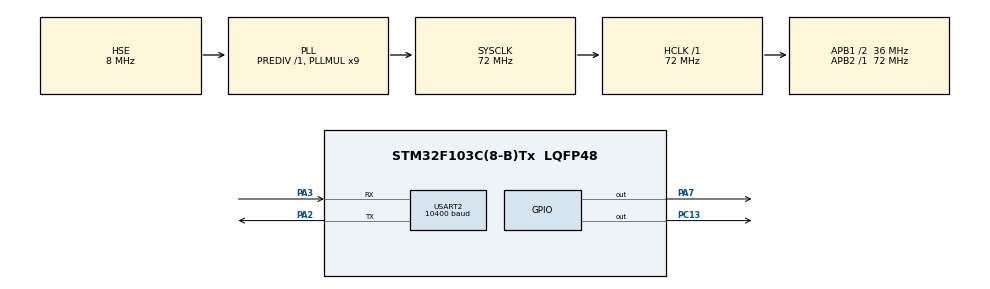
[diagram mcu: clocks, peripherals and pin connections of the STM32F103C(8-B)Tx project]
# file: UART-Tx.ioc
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Mcu.Family=STM32F1
Mcu.Name=STM32F103C(8-B)Tx
Mcu.Package=LQFP48
NVIC.PriorityGroup=NVIC_PRIORITYGROUP_4
NVIC.USART2_IRQn=true\:0\:0\:false\:false\:true\:true\:true\:true
PA13.Mode=Serial_Wire
PA13.Signal=SYS_JTMS-SWDIO
PA14.Mode=Serial_Wire
PA14.Signal=SYS_JTCK-SWCLK
PA2.Mode=Asynchronous
PA2.Signal=USART2_TX
PA3.Mode=Asynchronous
PA3.Signal=USART2_RX
PA7.Signal=GPIO_Output
PC13-TAMPER-RTC.Signal=GPIO_Output
PD0-OSC_IN.Mode=HSE-External-Oscillator
PD0-OSC_IN.Signal=RCC_OSC_IN
PD1-OSC_OUT.Mode=HSE-External-Oscillator
PD1-OSC_OUT.Signal=RCC_OSC_OUT
ProjectManager.HeapSize=0x200
ProjectManager.StackSize=0x400
ProjectManager.TargetToolchain=STM32CubeIDE
RCC.AHBFreq_Value=72000000
RCC.APB1CLKDivider=RCC_HCLK_DIV2
RCC.APB1Freq_Value=36000000
RCC.APB1TimFreq_Value=72000000
RCC.APB2Freq_Value=72000000
RCC.APB2TimFreq_Value=72000000
RCC.HCLKFreq_Value=72000000
RCC.PLLMUL=RCC_PLL_MUL9
RCC.PLLSourceVirtual=RCC_PLLSOURCE_HSE
RCC.SYSCLKFreq_VALUE=72000000
RCC.SYSCLKSource=RCC_SYSCLKSOURCE_PLLCLK
RCC.USBFreq_Value=48000000
RCC.USBPrescaler=RCC_USBCLKSOURCE_PLL_DIV1_5
USART2.BaudRate=10400
USART2.VirtualMode=VM_ASYNC
board=custom

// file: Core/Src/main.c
/* USER CODE BEGIN Header */
/**
  ******************************************************************************
  * @file           : main.c
  * @brief          : Main program body
  ******************************************************************************
  * @attention
  *
  * Copyright (c) 2023 STMicroelectronics.
  * All rights reserved.
  *
  * This software is licensed under terms that can be found in the LICENSE file
  * in the root directory of this software component.
  * If no LICENSE file comes with this software, it is provided AS-IS.
  *
  ******************************************************************************
  */
/* USER CODE END Header */
#include "main.h"

UART_HandleTypeDef huart2;

/* USER CODE BEGIN PV */
uint8_t rx_buffer[500];
uint8_t data_inico[]={0x81,0x10,0xF1,0x81,0x03}; // Arreglo de datos de solicitud de conexion
uint8_t data_enviar1[]={0x81,0x10,0xF1,0x3E,0xC0}; // Mensaje 1
uint8_t data_enviar2[]={0x83,0x10,0xF1,0x30,0x23,0x00,0xD7}; //Mensajer que activa rele

/* USER CODE END PV */

void SystemClock_Config(void);
static void MX_GPIO_Init(void);
static void MX_USART2_UART_Init(void);

int main(void)
{

  /* MCU Configuration--------------------------------------------------------*/

  /* Reset of all peripherals, Initializes the Flash interface and the Systick. */
  HAL_Init();

  /* Configure the system clock */
  SystemClock_Config();

  /* Initialize all configured peripherals */
  MX_GPIO_Init();
  MX_USART2_UART_Init();
  /* USER CODE BEGIN 2 */
  USART2->CR1 = 0x00;
  USART2->BRR=0x01;
  GPIOA->CRL|=0x02;
  GPIOA->BSRR=0x1;
  //HAL_UART_Receive_IT(&huart2, rx_buffer, sizeof(rx_buffer)); //Inicializacion de la Interrupcion de la uart
  /*
  HAL_GPIO_WritePin(GPIOA, GPIO_PIN_7, GPIO_PIN_RESET); //Pin de control de Mux. Al estar en bajo esta en el canal 0 que esta Tx uart
  HAL_Delay(2000); //esperamos 2 segundos para "limpiar la linea K"
  HAL_GPIO_WritePin(GPIOA, GPIO_PIN_7, GPIO_PIN_SET); //Ponemos el pin del mux en alto para seleccionar el canal 1 que esta en GND
  HAL_Delay(25); //eperamos 25ms por protocolo
  HAL_GPIO_WritePin(GPIOA, GPIO_PIN_7, GPIO_PIN_RESET); //volvemos al canal 0 del mux tx uart
  HAL_Delay(25); //esperamos otros 25ms por protocolo

  HAL_UART_Transmit_IT(&huart2, data_inico,sizeof(data_inico)); //tranmision de datos solicitud de conexion
  HAL_Delay(1000);
  HAL_UART_Transmit_IT(&huart2, data_enviar1,sizeof(data_enviar1)); //tranmision de datos
  HAL_Delay(1000);
  HAL_UART_Transmit_IT(&huart2, data_enviar2,sizeof(data_enviar2)); //tranmision de datos solicitud de conexion
  */
  /* USER CODE END 2 */

  /* Infinite loop */
  /* USER CODE BEGIN WHILE */
  while (1)
  {
	  GPIOC->BSRR |=(1<<13);
	  HAL_Delay(100);
	  GPIOC->BSRR |=(1<<29);
	  HAL_Delay(100);

    /* USER CODE END WHILE */

  }
}

void SystemClock_Config(void)
{
  RCC_OscInitTypeDef RCC_OscInitStruct = {0};
  RCC_ClkInitTypeDef RCC_ClkInitStruct = {0};

  /** Initializes the RCC Oscillators according to the specified parameters
  * in the RCC_OscInitTypeDef structure.
  */
  RCC_OscInitStruct.OscillatorType = RCC_OSCILLATORTYPE_HSE;
  RCC_OscInitStruct.HSEState = RCC_HSE_ON;
  RCC_OscInitStruct.HSEPredivValue = RCC_HSE_PREDIV_DIV1;
  RCC_OscInitStruct.HSIState = RCC_HSI_ON;
  RCC_OscInitStruct.PLL.PLLState = RCC_PLL_ON;
  RCC_OscInitStruct.PLL.PLLSource = RCC_PLLSOURCE_HSE;
  RCC_OscInitStruct.PLL.PLLMUL = RCC_PLL_MUL9;
  if (HAL_RCC_OscConfig(&RCC_OscInitStruct) != HAL_OK)
  {
    Error_Handler();
  }

  /** Initializes the CPU, AHB and APB buses clocks
  */
  RCC_ClkInitStruct.ClockType = RCC_CLOCKTYPE_HCLK|RCC_CLOCKTYPE_SYSCLK
                              |RCC_CLOCKTYPE_PCLK1|RCC_CLOCKTYPE_PCLK2;
  RCC_ClkInitStruct.SYSCLKSource = RCC_SYSCLKSOURCE_PLLCLK;
  RCC_ClkInitStruct.AHBCLKDivider = RCC_SYSCLK_DIV1;
  RCC_ClkInitStruct.APB1CLKDivider = RCC_HCLK_DIV2;
  RCC_ClkInitStruct.APB2CLKDivider = RCC_HCLK_DIV1;

  if (HAL_RCC_ClockConfig(&RCC_ClkInitStruct, FLASH_LATENCY_2) != HAL_OK)
  {
    Error_Handler();
  }
}

static void MX_USART2_UART_Init(void)
{

  huart2.Instance = USART2;
  huart2.Init.BaudRate = 10400;
  huart2.Init.WordLength = UART_WORDLENGTH_8B;
  huart2.Init.StopBits = UART_STOPBITS_1;
  huart2.Init.Parity = UART_PARITY_NONE;
  huart2.Init.Mode = UART_MODE_TX_RX;
  huart2.Init.HwFlowCtl = UART_HWCONTROL_NONE;
  huart2.Init.OverSampling = UART_OVERSAMPLING_16;
  if (HAL_UART_Init(&huart2) != HAL_OK)
  {
    Error_Handler();
  }

}

static void MX_GPIO_Init(void)
{
  GPIO_InitTypeDef GPIO_InitStruct = {0};

  /* GPIO Ports Clock Enable */
  __HAL_RCC_GPIOC_CLK_ENABLE();
  __HAL_RCC_GPIOD_CLK_ENABLE();
  __HAL_RCC_GPIOA_CLK_ENABLE();

  /*Configure GPIO pin Output Level */
  HAL_GPIO_WritePin(GPIOC, GPIO_PIN_13, GPIO_PIN_RESET);

  /*Configure GPIO pin Output Level */
  HAL_GPIO_WritePin(GPIOA, GPIO_PIN_7, GPIO_PIN_RESET);

  /*Configure GPIO pin : PC13 */
  GPIO_InitStruct.Pin = GPIO_PIN_13;
  GPIO_InitStruct.Mode = GPIO_MODE_OUTPUT_PP;
  GPIO_InitStruct.Pull = GPIO_NOPULL;
  GPIO_InitStruct.Speed = GPIO_SPEED_FREQ_LOW;
  HAL_GPIO_Init(GPIOC, &GPIO_InitStruct);

  /*Configure GPIO pin : PA7 */
  GPIO_InitStruct.Pin = GPIO_PIN_7;
  GPIO_InitStruct.Mode = GPIO_MODE_OUTPUT_PP;
  GPIO_InitStruct.Pull = GPIO_NOPULL;
  GPIO_InitStruct.Speed = GPIO_SPEED_FREQ_LOW;
  HAL_GPIO_Init(GPIOA, &GPIO_InitStruct);

}

void Error_Handler(void)
{
  __disable_irq();
  while (1)
  {
  }
}
